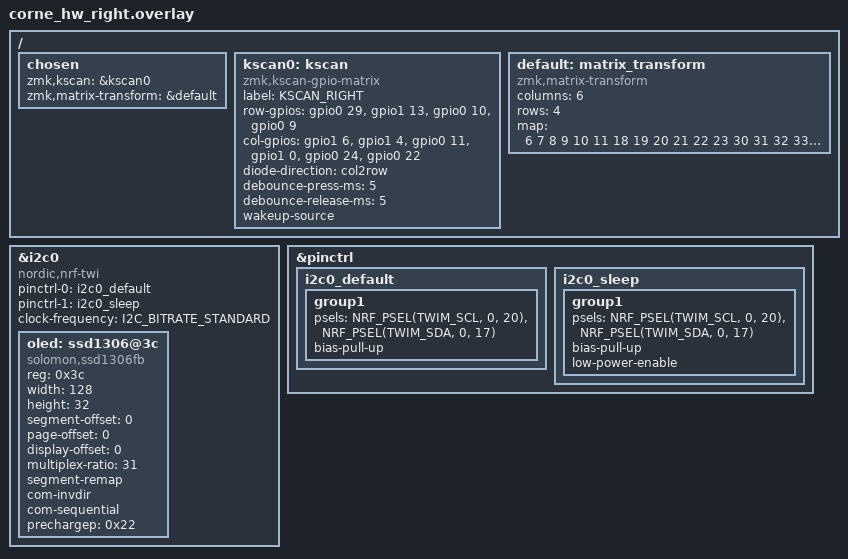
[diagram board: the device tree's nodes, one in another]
#include <dt-bindings/zmk/matrix_transform.h>
#include <zephyr/dt-bindings/pinctrl/nrf-pinctrl.h>
#include <dt-bindings/i2c/i2c.h>

/ {
    chosen { 
        zmk,kscan = &kscan0;
        zmk,matrix-transform = &default;
    };

    kscan0: kscan {
        compatible = "zmk,kscan-gpio-matrix";
        label = "KSCAN_RIGHT";
        /* Right half rows (top→bottom): P0.29, P1.13, P0.10, P0.09 */
        row-gpios = <&gpio0 29 (GPIO_ACTIVE_HIGH | GPIO_PULL_DOWN)>,
                    <&gpio1 13 (GPIO_ACTIVE_HIGH | GPIO_PULL_DOWN)>,
                    <&gpio0 10 (GPIO_ACTIVE_HIGH | GPIO_PULL_DOWN)>,
                    <&gpio0 9  (GPIO_ACTIVE_HIGH | GPIO_PULL_DOWN)>;
        /* Right half cols (left→right): P1.06, P1.04, P0.11, P1.00, P0.24, P0.22 */
        col-gpios = <&gpio1 6  GPIO_ACTIVE_HIGH>,
                    <&gpio1 4  GPIO_ACTIVE_HIGH>,
                    <&gpio0 11 GPIO_ACTIVE_HIGH>,
                    <&gpio1 0  GPIO_ACTIVE_HIGH>,
                    <&gpio0 24 GPIO_ACTIVE_HIGH>,
                    <&gpio0 22 GPIO_ACTIVE_HIGH>;
        diode-direction = "col2row";
        debounce-press-ms = <5>;
        debounce-release-ms = <5>;
        wakeup-source;
    };

    default: matrix_transform {
        compatible = "zmk,matrix-transform";
        columns = <6>;
        rows = <4>;
        /* Right rows to 12-wide positions (columns left→right): */
        map = <6 7 8 9 10 11  18 19 20 21 22 23  30 31 32 33 34 35  42 43 44 45 46 47>;
    };
};

&i2c0 {
    status = "okay";
    compatible = "nordic,nrf-twi";
    pinctrl-0 = <&i2c0_default>;
    pinctrl-1 = <&i2c0_sleep>;
    pinctrl-names = "default", "sleep";
    clock-frequency = <I2C_BITRATE_STANDARD>;

    oled: ssd1306@3c {
        compatible = "solomon,ssd1306fb";
        status = "okay";
        reg = <0x3c>;
        width = <128>;
        height = <32>;
        segment-offset = <0>;
        page-offset = <0>;
        display-offset = <0>;
        multiplex-ratio = <31>;
        segment-remap;
        com-invdir;
        com-sequential;
        prechargep = <0x22>;
    };
};

&pinctrl {
    i2c0_default: i2c0_default {
        group1 {
            psels = <NRF_PSEL(TWIM_SCL, 0, 20)>,
                    <NRF_PSEL(TWIM_SDA, 0, 17)>;
            bias-pull-up;
        };
    };

    i2c0_sleep: i2c0_sleep {
        group1 {
            psels = <NRF_PSEL(TWIM_SCL, 0, 20)>,
                    <NRF_PSEL(TWIM_SDA, 0, 17)>;
            bias-pull-up;
            low-power-enable;
        };
    };
};


